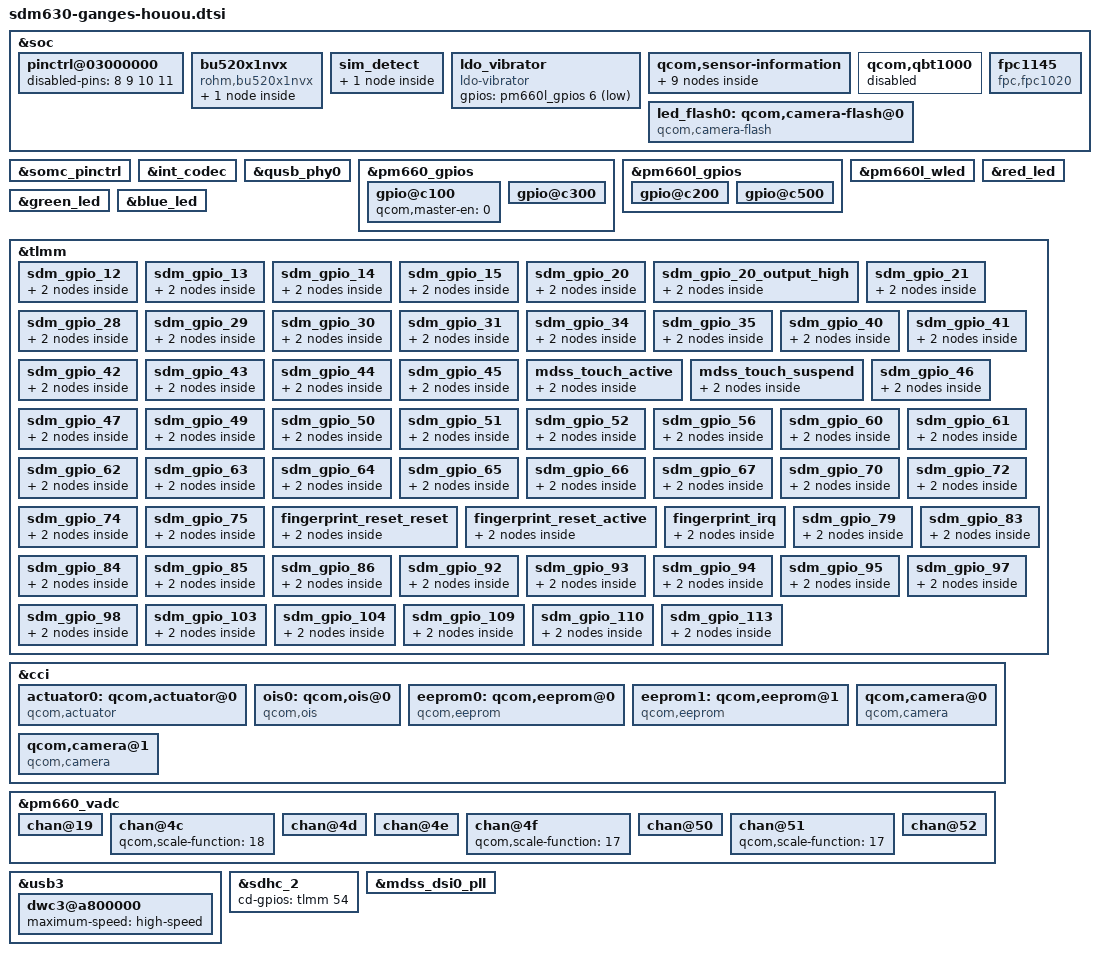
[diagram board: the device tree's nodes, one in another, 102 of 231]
/* arch/arm64/boot/dts/somc/sdm630-ganges-houou.dtsi
 *
 * This program is free software; you can redistribute it and/or modify
 * it under the terms of the GNU General Public License version 2 and
 * only version 2 as published by the Free Software Foundation.
 *
 * This program is distributed in the hope that it will be useful,
 * but WITHOUT ANY WARRANTY; without even the implied warranty of
 * MERCHANTABILITY or FITNESS FOR A PARTICULAR PURPOSE.  See the
 * GNU General Public License for more details.
*/
/*
 * Copyright (C) 2018 Sony Mobile Communications Inc.
 *
 * This program is free software; you can redistribute it and/or modify
 * it under the terms of the GNU General Public License version 2, as
 * published by the Free Software Foundation.
 */

#include "sdm630-ganges-common.dtsi"
#include "dsi-panel-houou.dtsi"
#include "sdm630-ganges-touch_houou.dtsi"
#include "charger-ganges-houou.dtsi"
#include "sdm630-ganges-nfc_carillon.dtsi"
#include <dt-bindings/gpio/gpio.h>

&soc {
	pinctrl@03000000 {
		disabled-pins = <8 9 10 11>;
	};

	bu520x1nvx {
		compatible = "rohm,bu520x1nvx";

		acc_cover {
			label = "lid";
			gpios = <&tlmm 75 0x1>;
			lid-pin = <1>;
			open-debounce-interval = <120>;
			close-debounce-interval = <300>;
		};
	};

	sim_detect {
		sim1_det {
			label = "sim-detection";
			gpios = <&tlmm 90 GPIO_ACTIVE_HIGH>;
			debounce-interval = <10>;
		};
	};

	ldo_vibrator {
		compatible = "ldo-vibrator";
		gpios = <&pm660l_gpios 6 1>;
	};

	qcom,sensor-information {
		/* msm_therm */
		sensor_information13: qcom,sensor-information-13 {
			qcom,scaling-factor = <1000>;
		};

		/* xo_therm */
		sensor_information14: qcom,sensor-information-14 {
			qcom,scaling-factor = <1000>;
		};

		/* pa_therm0 */
		sensor_information15: qcom,sensor-information-15 {
			qcom,scaling-factor = <1000>;
		};

		/* pa_therm1 */
		sensor_information16: qcom,sensor-information-16 {
			qcom,scaling-factor = <1000>;
		};

		/* quiet_therm */
		sensor_information17: qcom,sensor-information-17 {
			qcom,scaling-factor = <1000>;
			qcom,alias-name = "bl_therm";
		};

		/* sdm_therm */
		sensor_information100: qcom,sensor-information-100 {
			qcom,sensor-type = "adc";
			qcom,scaling-factor = <1000>;
			qcom,sensor-name = "sdm_therm";
		};

		/* emcp_therm */
		sensor_information101: qcom,sensor-information-101 {
			qcom,sensor-type = "adc";
			qcom,scaling-factor = <1000>;
			qcom,sensor-name = "emcp_therm";
		};

		/* flash_therm */
		sensor_information102: qcom,sensor-information-102 {
			qcom,sensor-type = "adc";
			qcom,sensor-name = "flash_therm";
			qcom,scaling-factor = <1000>;
		};

		/* bms */
		sensor_information103: qcom,sensor-information-103 {
			qcom,sensor-type = "adc";
			qcom,sensor-name = "bms";
			qcom,scaling-factor = <1000>;
			qcom,alias-name = "batt_therm";
		};
	};

	/* Disable QC fingerprint sensor */
	qcom,qbt1000 {
		status = "disabled";
	};

	fpc1145 {
		status = "ok";
		compatible = "fpc,fpc1020", "fpc1145";
		interrupt-parent = <&tlmm>;
		interrupts = <72 0x0>;
		fpc,gpio_rst    = <&tlmm 20 0x0>;
		fpc,gpio_irq    = <&tlmm 72 0x0>;
		vdd_ana-supply  = <&pm660l_bob>;
		vdd_ana-min-uV  = <3300000>;
		vdd_ana-max-uV  = <3600000>;

		gpio_ldo_enabe = <&pm660l_gpios 3 0x00>;
		pinctrl-names = "fpc1145_reset_reset",
				"fpc1145_reset_active",
				"fpc1145_irq_active";

		pinctrl-0 = <&fingerprint_reset_reset>;
		pinctrl-1 = <&fingerprint_reset_active>;
		pinctrl-2 = <&fingerprint_irq>;
	};

	led_flash0: qcom,camera-flash@0 {
		cell-index = <0>;
		compatible = "qcom,camera-flash";
		qcom,flash-source = <&pm660l_flash0>;
		qcom,torch-source = <&pm660l_torch0>;
		qcom,switch-source = <&pm660l_switch0>;
		status = "ok";
	};
};

&somc_pinctrl {
	/* If product common default setting is needed,
	fill pinctrl-1 value in <product>_common.dtsi */
	pinctrl-1 = <&sdm_gpio_12 &sdm_gpio_13 &sdm_gpio_14 &sdm_gpio_15 &sdm_gpio_20
		    &sdm_gpio_21 &sdm_gpio_28 &sdm_gpio_29 &sdm_gpio_30 &sdm_gpio_31
		    &sdm_gpio_34 &sdm_gpio_35 &sdm_gpio_40 &sdm_gpio_41 &sdm_gpio_42 &sdm_gpio_43
		    &sdm_gpio_44 &sdm_gpio_45 &sdm_gpio_46 &sdm_gpio_47 &sdm_gpio_49
		    &sdm_gpio_50 &sdm_gpio_51 &sdm_gpio_52 &sdm_gpio_56 &sdm_gpio_60
		    &sdm_gpio_61 &sdm_gpio_62 &sdm_gpio_63 &sdm_gpio_64 &sdm_gpio_65 &sdm_gpio_66
		    &sdm_gpio_67 &sdm_gpio_70 &sdm_gpio_72 &sdm_gpio_74 &sdm_gpio_75 &sdm_gpio_79
		    &sdm_gpio_83 &sdm_gpio_84 &sdm_gpio_85 &sdm_gpio_86 &sdm_gpio_92
		    &sdm_gpio_93 &sdm_gpio_94 &sdm_gpio_95 &sdm_gpio_97 &sdm_gpio_98
		    &sdm_gpio_103 &sdm_gpio_104 &sdm_gpio_109 &sdm_gpio_110 &sdm_gpio_113>;
};

&int_codec {
	qcom,msm-micbias1-ext-cap;
	/delete-property/ qcom,msm-micbias2-ext-cap;
	qcom,msm-hs-micbias-type = "external";
	qcom,audio-routing =
		"RX_BIAS", "INT_MCLK0",
		"SPK_RX_BIAS", "INT_MCLK0",
		"INT_LDO_H", "INT_MCLK0",
		"RX_I2S_CLK", "INT_MCLK0",
		"TX_I2S_CLK", "INT_MCLK0",
		"MIC BIAS External", "Handset Mic",
		"MIC BIAS External2", "Headset Mic",
		"MIC BIAS External", "Secondary Mic",
		"AMIC1", "MIC BIAS External",
		"AMIC2", "MIC BIAS External2",
		"AMIC3", "MIC BIAS External",
		"DMIC1", "MIC BIAS External",
		"MIC BIAS External", "Digital Mic1",
		"DMIC2", "MIC BIAS External",
		"MIC BIAS External", "Digital Mic2",
		"DMIC3", "MIC BIAS External",
		"MIC BIAS External", "Digital Mic3",
		"DMIC4", "MIC BIAS External",
		"MIC BIAS External", "Digital Mic4",
		"SpkrLeft IN", "SPK1 OUT",
		"SpkrRight IN", "SPK2 OUT",
		"PDM_IN_RX1", "PDM_OUT_RX1",
		"PDM_IN_RX2", "PDM_OUT_RX2",
		"PDM_IN_RX3", "PDM_OUT_RX3",
		"ADC1_IN", "ADC1_OUT",
		"ADC2_IN", "ADC2_OUT",
		"ADC3_IN", "ADC3_OUT";

	qcom,wsa-max-devs = <2>;
	qcom,wsa-devs = <&wsa881x_211_en>, <&wsa881x_212_en>,
			<&wsa881x_213_en>, <&wsa881x_214_en>;
	qcom,wsa-aux-dev-prefix = "SpkrLeft", "SpkrRight",
				  "SpkrLeft", "SpkrRight";
};

&qusb_phy0 {
	qcom,tune2-efuse-correction = <0>;
	qcom,qusb-phy-init-seq = <0xf8 0x80
			0xd3 0x84
			0x83 0x88
			0xc7 0x8c
			0x03 0x90
			0x30 0x08
			0x79 0x0c
			0x21 0x10
			0x14 0x9c
			0x9f 0x1c
			0x00 0x18>;
};

&pm660_gpios {
	/* GPIO_2: FLASH_THERM */
	gpio@c100 {
		status = "ok";
		qcom,master-en = <0>;		/* Disable */
	};

	gpio@c300 {
		qcom,mode = <0>;
		qcom,vin-sel = <1>;
		qcom,src-sel = <0>;
		qcom,master-en = <1>;
		status = "okay";
	};
};

&pm660l_gpios {
        gpio@c200 { /* GPIO3 - Fingerprint SENSOR LDO enable*/
                qcom,mode = <1>;                /* Output */
                qcom,pull = <5>;                /* No Pull */
                qcom,vin-sel = <0>;             /* VIN1 GPIO_LV */
                qcom,src-sel = <0>;             /* GPIO */
                qcom,master-en = <1>;           /* Enable GPIO */
                status = "ok";
        };
};

&pm660l_wled {
	qcom,ilim-ma = <620>;
	qcom,led-strings-list = [00 01 02];
};

&red_led {
	somc,color_variation_max_num = <5>;
	somc,max_current = <
		83 374 298
		84 106 104
		85 126 114
		86 106 104
		87 126 114>;
};

&green_led {
	somc,color_variation_max_num = <5>;
	somc,max_current = <
		83 398 488
		84 146 264
		85 180 286
		86 146 264
		87 180 286>;
};

&blue_led {
	somc,color_variation_max_num = <5>;
	somc,max_current = <
		83 510 246
		84 272 90
		85 406 106
		86 272 90
		87 406 106>;
};

&pm660l_gpios {
	/* GPIO_6: VIB_LDO_EN */
	gpio@c500 {
		qcom,src-sel = <0>;		/* GPIO */
		qcom,mode = <1>;		/* Out */
		qcom,output-type = <0>;		/* CMOS */
		qcom,vin-sel = <0>;		/* 1.8V */
		qcom,out-strength = <1>;	/* Low */
		qcom,invert = <0>;		/* Low */
		qcom,master-en = <1>;		/* Enable */
		status = "okay";
	};
};

&tlmm {
	/* GPIO_12: NC */
	sdm_gpio_12: sdm_gpio_12 {
		mux {
			pins = "gpio12";
			function = "gpio";
		};

		config {
			pins = "gpio12";
			drive-strength = <2>;
			bias-pull-down;
			input-enable;
		};
	};

	/* GPIO_13: NC */
	sdm_gpio_13: sdm_gpio_13 {
		mux {
			pins = "gpio13";
			function = "gpio";
		};

		config {
			pins = "gpio13";
			drive-strength = <2>;
			bias-pull-down;
			input-enable;
		};
	};

	/* GPIO_14: NC */
	sdm_gpio_14: sdm_gpio_14 {
		mux {
			pins = "gpio14";
			function = "gpio";
		};

		config {
			pins = "gpio14";
			drive-strength = <2>;
			bias-pull-down;
			input-enable;
		};
	};

	/* GPIO_15: NC */
	sdm_gpio_15: sdm_gpio_15 {
		mux {
			pins = "gpio15";
			function = "gpio";
		};

		config {
			pins = "gpio15";
			drive-strength = <2>;
			bias-pull-down;
			input-enable;
		};
	};

	/* GPIO_20 : FP_RESET_N */
	sdm_gpio_20: sdm_gpio_20 {
		mux {
			pins = "gpio20";
			function = "gpio";
		};

		config {
			pins = "gpio20";
			drive-strength = <2>;
			bias-disable;
			output-low;
		};
	};

	/* GPIO_20 : FP_RESET_N, state device active */
	sdm_gpio_20_output_high: sdm_gpio_20_output_high {
		mux {
			pins = "gpio20";
			function = "gpio";
		};

		config {
			pins = "gpio20";
			drive-strength = <2>;
			bias-disable;
			output-high;
		};
	};

	/* GPIO_21: NC */
	sdm_gpio_21: sdm_gpio_21 {
		mux {
			pins = "gpio21";
			function = "gpio";
		};

		config {
			pins = "gpio21";
			drive-strength = <2>;
			bias-pull-down;
			input-enable;
		};
	};

	/* GPIO_28: FELICA_INT_N */
	sdm_gpio_28: sdm_gpio_28 {
		mux {
			pins = "gpio28";
			function = "gpio";
		};

		config {
			pins = "gpio28";
			drive-strength = <2>;
			bias-pull-up;
			input-enable;
		};
	};

	/* GPIO_29: NC */
	sdm_gpio_29: sdm_gpio_29 {
		mux {
			pins = "gpio29";
			function = "gpio";
		};

		config {
			pins = "gpio29";
			drive-strength = <2>;
			bias-pull-down;
			input-enable;
		};
	};

	/* GPIO_30: FELICA_PON */
	sdm_gpio_30: sdm_gpio_30 {
		mux {
			pins = "gpio30";
			function = "gpio";
		};

		config {
			pins = "gpio30";
			drive-strength = <2>;
			bias-disable = <0>; /* no pull */
			output-low;
		};
	};

	/* GPIO_31: NC */
	sdm_gpio_31: sdm_gpio_31 {
		mux {
			pins = "gpio31";
			function = "gpio";
		};

		config {
			pins = "gpio31";
			drive-strength = <2>;
			bias-pull-down;
			input-enable;
		};
	};

	/* GPIO_34: NC */
	sdm_gpio_34: sdm_gpio_34 {
		mux {
			pins = "gpio34";
			function = "gpio";
		};

		config {
			pins = "gpio34";
			drive-strength = <2>;
			bias-pull-down;
			input-enable;
		};
	};

	/* GPIO_35: NC */
	sdm_gpio_35: sdm_gpio_35 {
		mux {
			pins = "gpio35";
			function = "gpio";
		};

		config {
			pins = "gpio35";
			drive-strength = <2>;
			bias-pull-down;
			input-enable;
		};
	};

	/* GPIO_40: NC */
	sdm_gpio_40: sdm_gpio_40 {
		mux {
			pins = "gpio40";
			function = "gpio";
		};

		config {
			pins = "gpio40";
			drive-strength = <2>;
			bias-pull-down;
			input-enable;
		};
	};

	/* GPIO_41: NC */
	sdm_gpio_41: sdm_gpio_41 {
		mux {
			pins = "gpio41";
			function = "gpio";
		};

		config {
			pins = "gpio41";
			drive-strength = <2>;
			bias-pull-down;
			input-enable;
		};
	};

	/* GPIO_42: NC */
	sdm_gpio_42: sdm_gpio_42 {
		mux {
			pins = "gpio42";
			function = "gpio";
		};

		config {
			pins = "gpio42";
			drive-strength = <2>;
			bias-pull-down;
			input-enable;
		};
	};

	/* GPIO_43: NC */
	sdm_gpio_43: sdm_gpio_43 {
		mux {
			pins = "gpio43";
			function = "gpio";
		};

		config {
			pins = "gpio43";
			drive-strength = <2>;
			bias-pull-down;
			input-enable;
		};
	};

	/* GPIO_44: NC */
	sdm_gpio_44: sdm_gpio_44 {
		mux {
			pins = "gpio44";
			function = "gpio";
		};

		config {
			pins = "gpio44";
			drive-strength = <2>;
			bias-pull-down;
			input-enable;
		};
	};

	/* GPIO_45 : TS_INT_N */
	sdm_gpio_45: sdm_gpio_45 {
		mux {
			pins = "gpio45";
			function = "gpio";
		};

		config {
			pins = "gpio45";
			drive-strength = <2>;
			bias-pull-down;
			input-enable;
		};
	};

	mdss_touch_active: mdss_touch_active {
		mux {
			pins = "gpio45";
			function = "gpio";
		};

		config {
			pins = "gpio45";
			drive-strength = <2>;
			bias-pull-up;
		};
	};

	mdss_touch_suspend: mdss_touch_suspend {
		mux {
			pins = "gpio45";
			function = "gpio";
		};

		config {
			pins = "gpio45";
			drive-strength = <2>;
			bias-pull-down;
		};
	};

	/* GPIO_46 : CAM0_RST_N */
	sdm_gpio_46: sdm_gpio_46 {
		mux {
			pins = "gpio46";
			function = "gpio";
		};

		config {
			pins = "gpio46";
			drive-strength = <2>;
			bias-disable;
			output-low;
		};
	};

	/* GPIO_47 : CAM2_RST_N */
	sdm_gpio_47: sdm_gpio_47 {
		mux {
			pins = "gpio47";
			function = "gpio";
		};

		config {
			pins = "gpio47";
			drive-strength = <2>;
			bias-disable;
			output-low;
		};
	};

	/* GPIO_49: NC */
	sdm_gpio_49: sdm_gpio_49 {
		mux {
			pins = "gpio49";
			function = "gpio";
		};

		config {
			pins = "gpio49";
			drive-strength = <2>;
			bias-pull-down;
			input-enable;
		};
	};

	/* GPIO_50 : MAIN_CAM_PWR_EN */
	sdm_gpio_50: sdm_gpio_50 {
		mux {
			pins = "gpio50";
			function = "gpio";
		};

		config {
			pins = "gpio50";
			drive-strength = <2>;
			bias-disable;
			output-low;
		};
	};

	/* GPIO_51 : CHAT_CAM_PWR_EN */
	sdm_gpio_51: sdm_gpio_51 {
		mux {
			pins = "gpio51";
			function = "gpio";
		};

		config {
			pins = "gpio51";
			drive-strength = <2>;
			bias-disable;
			output-low;
		};
	};

	/* GPIO_52 : CAM_IO_EN */
	sdm_gpio_52: sdm_gpio_52 {
		mux {
			pins = "gpio52";
			function = "gpio";
		};

		config {
			pins = "gpio52";
			drive-strength = <2>;
			bias-disable;
			output-low;
		};
	};

	/* GPIO_56: NC */
	sdm_gpio_56: sdm_gpio_56 {
		mux {
			pins = "gpio56";
			function = "gpio";
		};

		config {
			pins = "gpio56";
			drive-strength = <2>;
			bias-pull-down;
			input-enable;
		};
	};

	/* GPIO_60: NC */
	sdm_gpio_60: sdm_gpio_60 {
		mux {
			pins = "gpio60";
			function = "gpio";
		};

		config {
			pins = "gpio60";
			drive-strength = <2>;
			bias-pull-down;
			input-enable;
		};
	};

	/* GPIO_61 : USB_DETECT_EN */
	 sdm_gpio_61: sdm_gpio_61 {
		mux {
			pins = "gpio61";
			function = "gpio";
		};

		config {
			pins = "gpio61";
			drive-strength = <2>;
			bias-disable;
			output-low;
		};
	};

	/* GPIO_62: DEBUG_GPIO0 */
	sdm_gpio_62: sdm_gpio_62 {
		mux {
			pins = "gpio62";
			function = "gpio";
		};

		config {
			pins = "gpio62";
			drive-strength = <2>;
			bias-disable;
			output-low;
		};
	};

	/* GPIO_63: NC */
	sdm_gpio_63: sdm_gpio_63 {
		mux {
			pins = "gpio63";
			function = "gpio";
		};

		config {
			pins = "gpio63";
			drive-strength = <2>;
			bias-pull-down;
			input-enable;
		};
	};

	/* GPIO_64: NC */
	sdm_gpio_64: sdm_gpio_64 {
		mux {
			pins = "gpio64";
			function = "gpio";
		};

		config {
			pins = "gpio64";
			drive-strength = <2>;
			bias-pull-down;
			input-enable;
		};
	};

	/* GPIO_65: NC */
	sdm_gpio_65: sdm_gpio_65 {
		mux {
			pins = "gpio65";
			function = "gpio";
		};

		config {
			pins = "gpio65";
			drive-strength = <2>;
			bias-pull-down;
			input-enable;
		};
	};

	/* GPIO_66 : TS_RESET_N */
	sdm_gpio_66: sdm_gpio_66 {
		mux {
			pins = "gpio66";
			function = "gpio";
		};

		config {
			pins = "gpio66";
			drive-strength = <2>;
			bias-disable;
			output-low;
		};
	};

	/* GPIO_67: NC */
	sdm_gpio_67: sdm_gpio_67 {
		mux {
			pins = "gpio67";
			function = "gpio";
		};

		config {
			pins = "gpio67";
			drive-strength = <2>;
			bias-pull-down;
			input-enable;
		};
	};

	/* GPIO_70: NC */
	sdm_gpio_70: sdm_gpio_70 {
		mux {
			pins = "gpio70";
			function = "gpio";
		};

		config {
			pins = "gpio70";
			drive-strength = <2>;
			bias-pull-down;
			input-enable;
		};
	};

	/* GPIO_72 : FP_INT_N */
	sdm_gpio_72: sdm_gpio_72 {
		mux {
			pins = "gpio72";
			function = "gpio";
		};

		config {
			pins = "gpio72";
			drive-strength = <2>;
			bias-pull-down;
			input-enable;
		};
	};

	/* GPIO_74: DEBUG_GPIO1 */
	sdm_gpio_74: sdm_gpio_74 {
		mux {
			pins = "gpio74";
			function = "gpio";
		};

		config {
			pins = "gpio74";
			drive-strength = <2>;
			bias-disable;
			output-low;
		};
	};

	/* GPIO_75 : ACC_COVER_OPEN */
	sdm_gpio_75: sdm_gpio_75 {
		mux {
			pins = "gpio75";
			function = "gpio";
		};

		config {
			pins = "gpio75";
			drive-strength = <2>;
			bias-disable;
			input-enable;
		};
	};

	/* GPIO_20 : FP_RESET_N */
	fingerprint_reset_reset: fingerprint_reset_reset {
		mux {
			pins = "gpio20";
			function = "gpio";
		};

		config {
			pins = "gpio20";
			drive-strength = <2>;
			bias-disable;
			output-low;
		};
	};

	/* GPIO_20 : FP_RESET_N, state device active */
	fingerprint_reset_active: fingerprint_reset_active {
		mux {
			pins = "gpio20";
			function = "gpio";
		};

		config {
			pins = "gpio20";
			drive-strength = <2>;
			bias-disable;
			output-high;
		};
	};

	/* GPIO_72 : FP_INT_N */
	fingerprint_irq: fingerprint_irq {
		mux {
			pins = "gpio72";
			function = "gpio";
		};

		config {
			pins = "gpio72";
			drive-strength = <2>;
			bias-pull-down;
			input-enable;
		};
	};

	/* GPIO_79: NC */
	sdm_gpio_79: sdm_gpio_79 {
		mux {
			pins = "gpio79";
			function = "gpio";
		};

		config {
			pins = "gpio79";
			drive-strength = <2>;
			bias-pull-down;
			input-enable;
		};
	};

	/* GPIO_83: NC */
	sdm_gpio_83: sdm_gpio_83 {
		mux {
			pins = "gpio83";
			function = "gpio";
		};

		config {
			pins = "gpio83";
			drive-strength = <2>;
			bias-pull-down;
			input-enable;
		};
	};

	/* GPIO_84: NC */
	sdm_gpio_84: sdm_gpio_84 {
		mux {
			pins = "gpio84";
			function = "gpio";
		};

		config {
			pins = "gpio84";
			drive-strength = <2>;
			bias-pull-down;
			input-enable;
		};
	};

	/* GPIO_85: NC */
	sdm_gpio_85: sdm_gpio_85 {
		mux {
			pins = "gpio85";
			function = "gpio";
		};

		config {
			pins = "gpio85";
			drive-strength = <2>;
			bias-pull-down;
			input-enable;
		};
	};

	/* GPIO_86: NC */
	sdm_gpio_86: sdm_gpio_86 {
		mux {
			pins = "gpio86";
			function = "gpio";
		};

		config {
			pins = "gpio86";
			drive-strength = <2>;
			bias-pull-down;
			input-enable;
		};
	};

	/* GPIO_: NC */
	sdm_gpio_92: sdm_gpio_92 {
		mux {
			pins = "gpio92";
			function = "gpio";
		};

		config {
			pins = "gpio92";
			drive-strength = <2>;
			bias-pull-down;
			input-enable;
		};
	};

	/* GPIO_93: NC */
	sdm_gpio_93: sdm_gpio_93 {
		mux {
			pins = "gpio93";
			function = "gpio";
		};

		config {
			pins = "gpio93";
			drive-strength = <2>;
			bias-pull-down;
			input-enable;
		};
	};

	/* GPIO_94: NC */
	sdm_gpio_94: sdm_gpio_94 {
		mux {
			pins = "gpio94";
			function = "gpio";
		};

		config {
			pins = "gpio94";
			drive-strength = <2>;
			bias-pull-down;
			input-enable;
		};
	};

	/* GPIO_: NC */
	sdm_gpio_95: sdm_gpio_95 {
		mux {
			pins = "gpio95";
			function = "gpio";
		};

		config {
			pins = "gpio95";
			drive-strength = <2>;
			bias-pull-down;
			input-enable;
		};
	};

	/* GPIO_97: NC */
	sdm_gpio_97: sdm_gpio_97 {
		mux {
			pins = "gpio97";
			function = "gpio";
		};

		config {
			pins = "gpio97";
			drive-strength = <2>;
			bias-pull-down;
			input-enable;
		};
	};

	/* GPIO_98: NC */
	sdm_gpio_98: sdm_gpio_98 {
		mux {
			pins = "gpio98";
			function = "gpio";
		};

		config {
			pins = "gpio98";
			drive-strength = <2>;
			bias-pull-down;
			input-enable;
		};
	};

	/* GPIO_103: NC */
	sdm_gpio_103: sdm_gpio_103 {
		mux {
			pins = "gpio103";
			function = "gpio";
		};

		config {
			pins = "gpio103";
			drive-strength = <2>;
			bias-pull-down;
			input-enable;
		};
	};

	/* GPIO_104: NC */
	sdm_gpio_104: sdm_gpio_104 {
		mux {
			pins = "gpio104";
			function = "gpio";
		};

		config {
			pins = "gpio104";
			drive-strength = <2>;
			bias-pull-down;
			input-enable;
		};
	};

	/* GPIO_109: NC */
	sdm_gpio_109: sdm_gpio_109 {
		mux {
			pins = "gpio109";
			function = "gpio";
		};

		config {
			pins = "gpio109";
			drive-strength = <2>;
			bias-pull-down;
			input-enable;
		};
	};

	/* GPIO_110: NC */
	sdm_gpio_110: sdm_gpio_110 {
		mux {
			pins = "gpio110";
			function = "gpio";
		};

		config {
			pins = "gpio110";
			drive-strength = <2>;
			bias-pull-down;
			input-enable;
		};
	};

	/* GPIO_113: NC */
	sdm_gpio_113: sdm_gpio_113 {
		mux {
			pins = "gpio113";
			function = "gpio";
		};

		config {
			pins = "gpio113";
			drive-strength = <2>;
			bias-pull-down;
			input-enable;
		};
	};
};

&cci {
	actuator0: qcom,actuator@0 {
		cell-index = <0>;
		compatible = "qcom,actuator";
		reg = <0x0>;
		qcom,cci-master = <0>;
		status = "ok";
	};

	ois0: qcom,ois@0 {
		cell-index = <0>;
		compatible = "qcom,ois";
		reg = <0x0>;
		qcom,csiphy-sd-index = <0>;
		qcom,csid-sd-index = <0>;
		qcom,cci-master = <0>;
		status = "ok";
		pinctrl-names = "cam_default", "cam_suspend";
		pinctrl-0 = <>;
		pinctrl-1 = <>;
	};

	eeprom0: qcom,eeprom@0 {
		cell-index = <0>;
		compatible = "qcom,eeprom";
		reg = <0x0>;
		qcom,csiphy-sd-index = <0>;
		qcom,csid-sd-index = <0>;
		qcom,mount-angle = <90>;
		cam_vio-supply = <&pm660_s4>;
		cam_vaf-supply = <&pm660l_l3>;
		cam_vana-supply = <&pm660_s5>;
		qcom,cam-vreg-name = "cam_vio", "cam_vaf", "cam_vana";
		qcom,cam-vreg-min-voltage = <2040000 2800000 1350000>;
		qcom,cam-vreg-max-voltage = <2040000 2800000 1350000>;
		qcom,cam-vreg-op-mode = <105000 105000 105000>;
		qcom,gpio-no-mux = <0>;
		pinctrl-names = "cam_default", "cam_suspend";
		pinctrl-0 = <&cam_sensor_mclk0_active
				 &sdm_gpio_46 &sdm_gpio_52 &sdm_gpio_50>;
		pinctrl-1 = <&cam_sensor_mclk0_suspend
				 &sdm_gpio_46 &sdm_gpio_52 &sdm_gpio_50>;
		gpios = <&tlmm 32 0>,
			<&tlmm 46 0>,
			<&tlmm 52 0>,
			<&tlmm 50 0>;
		qcom,gpio-reset = <1>;
		qcom,gpio-vio = <2>;
		qcom,gpio-vana = <3>;
		qcom,gpio-req-tbl-num = <0 1 2 3>;
		qcom,gpio-req-tbl-flags = <1 0 0 0>;
		qcom,gpio-req-tbl-label = "CAMIF_MCLK0",
					"CAM_RESET0",
					"CAM_VIO",
					"CAM_VANA";
		qcom,sensor-position = <0>;
		qcom,sensor-mode = <0>;
		qcom,cci-master = <0>;
		status = "ok";
		clocks = <&clock_mmss MCLK0_CLK_SRC>,
				<&clock_mmss MMSS_CAMSS_MCLK0_CLK>;
		clock-names = "cam_src_clk", "cam_clk";
		qcom,clock-rates = <24000000 0>;
	};

	eeprom1: qcom,eeprom@1 {
		cell-index = <1>;
		compatible = "qcom,eeprom";
		reg = <0x01>;
		qcom,csiphy-sd-index = <2>;
		qcom,csid-sd-index = <2>;
		qcom,mount-angle = <0>;
		cam_vio-supply = <&pm660_s4>;
		cam_vana-supply = <&pm660_s5>;
		qcom,cam-vreg-name = "cam_vio", "cam_vana";
		qcom,cam-vreg-min-voltage = <2040000 1350000>;
		qcom,cam-vreg-max-voltage = <2040000 1350000>;
		qcom,cam-vreg-op-mode = <105000 105000>;
		qcom,gpio-no-mux = <0>;
		pinctrl-names = "cam_default", "cam_suspend";
		pinctrl-0 = <&cam_sensor_mclk1_active
				 &sdm_gpio_47 &sdm_gpio_52 &sdm_gpio_51>;
		pinctrl-1 = <&cam_sensor_mclk1_suspend
				 &sdm_gpio_47 &sdm_gpio_52 &sdm_gpio_51>;
		gpios = <&tlmm 33 0>,
			<&tlmm 47 0>,
			<&tlmm 52 0>,
			<&tlmm 51 0>;
		qcom,gpio-reset = <1>;
		qcom,gpio-vio = <2>;
		qcom,gpio-vana = <3>;
		qcom,gpio-req-tbl-num = <0 1 2 3>;
		qcom,gpio-req-tbl-flags = <1 0 0 0>;
		qcom,gpio-req-tbl-label = "CAMIF_MCLK1",
					"CAM_RESET1",
					"CAM_VIO1",
					"CAM_VANA1";
		qcom,sensor-position = <1>;
		qcom,sensor-mode = <0>;
		qcom,cci-master = <1>;
		status = "ok";
		clocks = <&clock_mmss MCLK1_CLK_SRC>,
			<&clock_mmss MMSS_CAMSS_MCLK1_CLK>;
		clock-names = "cam_src_clk", "cam_clk";
		qcom,clock-rates = <24000000 0>;
	};

	qcom,camera@0 {
		cell-index = <0>;
		compatible = "qcom,camera";
		reg = <0x0>;
		qcom,csiphy-sd-index = <0>;
		qcom,csid-sd-index = <0>;
		qcom,mount-angle = <90>;
		qcom,led-flash-src = <&led_flash0>;
		qcom,actuator-src = <&actuator0>;
		qcom,eeprom-src = <&eeprom0>;
		qcom,ois-src = <&ois0>;
		cam_vio-supply = <&pm660_s4>;
		cam_vaf-supply = <&pm660l_l3>;
		cam_vana-supply = <&pm660_s5>;
		qcom,cam-vreg-name = "cam_vio", "cam_vaf", "cam_vana";
		qcom,cam-vreg-min-voltage = <2040000 2800000 1350000>;
		qcom,cam-vreg-max-voltage = <2040000 2800000 1350000>;
		qcom,cam-vreg-op-mode = <105000 105000 105000>;
		qcom,gpio-no-mux = <0>;
		pinctrl-names = "cam_default", "cam_suspend";
		pinctrl-0 = <&cam_sensor_mclk0_active
				 &sdm_gpio_46 &sdm_gpio_52 &sdm_gpio_50>;
		pinctrl-1 = <&cam_sensor_mclk0_suspend
				 &sdm_gpio_46 &sdm_gpio_52 &sdm_gpio_50>;
		gpios = <&tlmm 32 0>,
			<&tlmm 46 0>,
			<&tlmm 52 0>,
			<&tlmm 50 0>;
		qcom,gpio-reset = <1>;
		qcom,gpio-vio = <2>;
		qcom,gpio-vana = <3>;
		qcom,gpio-req-tbl-num = <0 1 2 3>;
		qcom,gpio-req-tbl-flags = <1 0 0 0>;
		qcom,gpio-req-tbl-label = "CAMIF_MCLK0",
					"CAM_RESET0",
					"CAM_VIO",
					"CAM_VANA";
		qcom,sensor-position = <0>;
		qcom,sensor-mode = <0>;
		qcom,cci-master = <0>;
		status = "ok";
		clocks = <&clock_mmss MCLK0_CLK_SRC>,
				<&clock_mmss MMSS_CAMSS_MCLK0_CLK>;
		clock-names = "cam_src_clk", "cam_clk";
		qcom,clock-rates = <24000000 0>;
	};

	qcom,camera@1 {
		cell-index = <1>;
		compatible = "qcom,camera";
		reg = <0x01>;
		qcom,csiphy-sd-index = <2>;
		qcom,csid-sd-index = <2>;
		qcom,mount-angle = <0>;
		qcom,eeprom-src = <&eeprom1>;
		cam_vio-supply = <&pm660_s4>;
		cam_vana-supply = <&pm660_s5>;
		qcom,cam-vreg-name = "cam_vio", "cam_vana";
		qcom,cam-vreg-min-voltage = <2040000 1350000>;
		qcom,cam-vreg-max-voltage = <2040000 1350000>;
		qcom,cam-vreg-op-mode = <105000 105000>;
		qcom,gpio-no-mux = <0>;
		pinctrl-names = "cam_default", "cam_suspend";
		pinctrl-0 = <&cam_sensor_mclk1_active
				 &sdm_gpio_47 &sdm_gpio_52 &sdm_gpio_51>;
		pinctrl-1 = <&cam_sensor_mclk1_suspend
				 &sdm_gpio_47 &sdm_gpio_52 &sdm_gpio_51>;
		gpios = <&tlmm 33 0>,
			<&tlmm 47 0>,
			<&tlmm 52 0>,
			<&tlmm 51 0>;
		qcom,gpio-reset = <1>;
		qcom,gpio-vio = <2>;
		qcom,gpio-vana = <3>;
		qcom,gpio-req-tbl-num = <0 1 2 3>;
		qcom,gpio-req-tbl-flags = <1 0 0 0>;
		qcom,gpio-req-tbl-label = "CAMIF_MCLK1",
					"CAM_RESET1",
					"CAM_VIO1",
					"CAM_VANA1";
		qcom,sensor-position = <1>;
		qcom,sensor-mode = <0>;
		qcom,cci-master = <1>;
		status = "ok";
		clocks = <&clock_mmss MCLK1_CLK_SRC>,
			<&clock_mmss MMSS_CAMSS_MCLK1_CLK>;
		clock-names = "cam_src_clk", "cam_clk";
		qcom,clock-rates = <24000000 0>;
	};
};

&pm660_vadc {
	chan@19 { /* USB_DETECT_ADC */
		label = "usb_detect";
		reg = <0x19>;
		qcom,decimation = <0>;
		qcom,pre-div-channel-scaling = <0>;
		qcom,calibration-type = "absolute";
		qcom,scale-function = <0>;
		qcom,hw-settle-time = <5>;
		qcom,fast-avg-setup = <0>;
	};

	chan@4c { /* XO_THERM */
		qcom,scale-function = <18>;
	};

	chan@4d { /* Rename from msm_therm */
		label = "sdm_therm";
		qcom,scale-function = <17>;
		qcom,vadc-thermal-node;
	};

	chan@4e { /* Rename from emmc_therm */
		label = "emcp_therm";
		qcom,scale-function = <17>;
	};

	chan@4f { /* pa_therm0 */
		qcom,scale-function = <17>;
	};

	chan@50 {
		label = "pa_therm1";
		reg = <0x50>;
		qcom,decimation = <2>;
		qcom,pre-div-channel-scaling = <0>;
		qcom,calibration-type = "ratiometric";
		qcom,scale-function = <17>;
		qcom,hw-settle-time = <2>;
		qcom,fast-avg-setup = <0>;
		qcom,vadc-thermal-node;
	};

	chan@51 { /* quiet_therm */
		qcom,scale-function = <17>;
	};

	chan@52 {
		label = "flash_therm";
		reg = <0x52>;
		qcom,decimation = <2>;
		qcom,pre-div-channel-scaling = <0>;
		qcom,calibration-type = "ratiometric";
		qcom,scale-function = <17>;
		qcom,hw-settle-time = <2>;
		qcom,fast-avg-setup = <0>;
		qcom,vadc-thermal-node;
	};
};

&usb3 {
	id_polling_use;
	id_polling_up_interval = <2000>;
	id_polling_up_period = <0>;
	id_polling_pd_gpio = <&tlmm 61 0>;
	qcom,usb_detect-vadc = <&pm660_vadc>;
	dwc3@a800000 {
		maximum-speed = "high-speed";
	};
};

&sdhc_2 {
	cd-gpios = <&tlmm 54 GPIO_ACTIVE_HIGH>;
};

&mdss_dsi0_pll {
	/delete-property/ qcom,dsi-pll-ssc-en;
};
